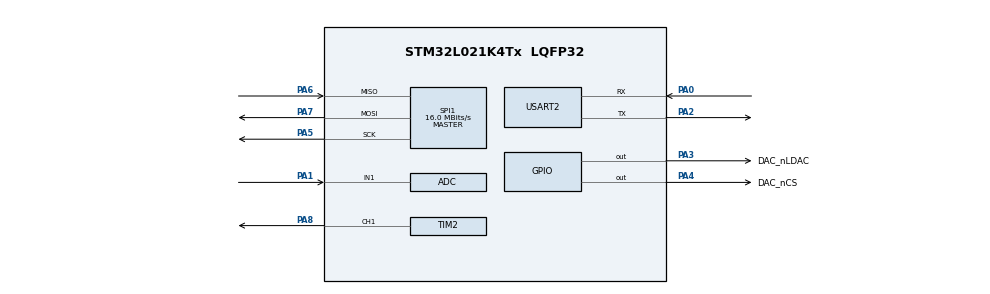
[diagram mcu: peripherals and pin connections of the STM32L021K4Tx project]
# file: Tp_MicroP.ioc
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Mcu.Family=STM32L0
Mcu.Name=STM32L021K4Tx
Mcu.Package=LQFP32
NVIC.TIM21_IRQn=true\:0\:0\:false\:false\:true\:true\:true\:true
PA0-CK_IN.Mode=Asynchronous
PA0-CK_IN.Signal=USART2_RX
PA1.Mode=IN1
PA1.Signal=ADC_IN1
PA13.Mode=Serial_Wire
PA13.Signal=SYS_SWDIO
PA14.Mode=Serial_Wire
PA14.Signal=SYS_SWCLK
PA2.Mode=Asynchronous
PA2.Signal=USART2_TX
PA3.GPIO_Label=DAC_nLDAC
PA3.Signal=GPIO_Output
PA4.GPIO_Label=DAC_nCS
PA4.Signal=GPIO_Output
PA5.Mode=Full_Duplex_Master
PA5.Signal=SPI1_SCK
PA6.Mode=Full_Duplex_Master
PA6.Signal=SPI1_MISO
PA7.Mode=Full_Duplex_Master
PA7.Signal=SPI1_MOSI
PA8.Signal=S_TIM2_CH1
ProjectManager.HeapSize=0x200
ProjectManager.StackSize=0x400
ProjectManager.TargetToolchain=STM32CubeIDE
RCC.AHBFreq_Value=32000000
RCC.APB1Freq_Value=32000000
RCC.APB1TimFreq_Value=32000000
RCC.APB2Freq_Value=32000000
RCC.APB2TimFreq_Value=32000000
RCC.HCLKFreq_Value=32000000
RCC.HSE_VALUE=8000000
RCC.HSI16_VALUE=16000000
RCC.HSI_VALUE=16000000
RCC.LSE_VALUE=32768
RCC.MSIClockRange=RCC_MSIRANGE_6
RCC.MSI_VALUE=4194000
RCC.PLLMUL=RCC_PLLMUL_4
RCC.SYSCLKFreq_VALUE=32000000
RCC.SYSCLKSource=RCC_SYSCLKSOURCE_PLLCLK
RCC.VCOOutputFreq_Value=64000000
SH.S_TIM2_CH1.0=TIM2_CH1,PWM Generation1 CH1
SPI1.CalculateBaudRate=16.0 MBits/s
SPI1.Direction=SPI_DIRECTION_2LINES
SPI1.Mode=SPI_MODE_MASTER
SPI1.VirtualType=VM_MASTER
TIM2.Channel-PWM\ Generation1\ CH1=TIM_CHANNEL_1
TIM2.Period=255
TIM2.Prescaler=125
TIM21.Period=255
TIM21.Prescaler=125
USART2.VirtualMode-Asynchronous=VM_ASYNC
VP_TIM21_VS_ClockSourceINT.Mode=Internal
VP_TIM2_VS_ClockSourceINT.Mode=Internal
board=custom

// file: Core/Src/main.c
/* USER CODE BEGIN Header */
/**
 ******************************************************************************
 * @file           : main.c
 * @brief          : Main program body
 ******************************************************************************
 * @attention
 *
 * <h2><center>&copy; Copyright (c) 2023 STMicroelectronics.
 * All rights reserved.</center></h2>
 *
 * This software component is licensed by ST under BSD 3-Clause license,
 * the "License"; You may not use this file except in compliance with the
 * License. You may obtain a copy of the License at:
 *                        opensource.org/licenses/BSD-3-Clause
 *
 ******************************************************************************
 */
/* USER CODE END Header */
#include "main.h"
#include "adc.h"
#include "spi.h"
#include "tim.h"
#include "usart.h"
#include "gpio.h"

/* USER CODE BEGIN Includes */
#include "Led.h"
/* USER CODE END Includes */

void SystemClock_Config(void);

/* USER CODE BEGIN 0 */
led_t MyLed = {
	.value = 0,
	.sens = LED_UP,
	.timer = TIM2
};

//Fonction appelé lors d'une interruption
/*void HAL_TIM_PeriodElapsedCallback(TIM_HandleTypeDef *htim){
  	if (htim==&htim21)

	}*/
/* USER CODE END 0 */

int main(void)
{

  /* MCU Configuration--------------------------------------------------------*/

  /* Reset of all peripherals, Initializes the Flash interface and the Systick. */
  HAL_Init();

  /* Configure the system clock */
  SystemClock_Config();

  /* Initialize all configured peripherals */
  MX_GPIO_Init();
  MX_USART2_UART_Init();
  MX_ADC_Init();
  MX_TIM2_Init();
  MX_SPI1_Init();
  MX_TIM21_Init();
  /* USER CODE BEGIN 2 */
  //démarrage de l'interruption sur TIM21
  HAL_TIM_Base_Start_IT(&htim21);
  LedStart(&MyLed);
  /* USER CODE END 2 */

  /* Infinite loop */
  /* USER CODE BEGIN WHILE */
	while (1)
	{
		LedPulse(&MyLed);
		LL_mDelay(1);
    /* USER CODE END WHILE */

	}
}

void SystemClock_Config(void)
{
  LL_FLASH_SetLatency(LL_FLASH_LATENCY_1);
  while(LL_FLASH_GetLatency()!= LL_FLASH_LATENCY_1)
  {
  }
  LL_PWR_SetRegulVoltageScaling(LL_PWR_REGU_VOLTAGE_SCALE1);
  LL_RCC_HSI_Enable();

   /* Wait till HSI is ready */
  while(LL_RCC_HSI_IsReady() != 1)
  {

  }
  LL_RCC_HSI_SetCalibTrimming(16);
  LL_RCC_PLL_ConfigDomain_SYS(LL_RCC_PLLSOURCE_HSI, LL_RCC_PLL_MUL_4, LL_RCC_PLL_DIV_2);
  LL_RCC_PLL_Enable();

   /* Wait till PLL is ready */
  while(LL_RCC_PLL_IsReady() != 1)
  {

  }
  LL_RCC_SetAHBPrescaler(LL_RCC_SYSCLK_DIV_1);
  LL_RCC_SetAPB1Prescaler(LL_RCC_APB1_DIV_1);
  LL_RCC_SetAPB2Prescaler(LL_RCC_APB2_DIV_1);
  LL_RCC_SetSysClkSource(LL_RCC_SYS_CLKSOURCE_PLL);

   /* Wait till System clock is ready */
  while(LL_RCC_GetSysClkSource() != LL_RCC_SYS_CLKSOURCE_STATUS_PLL)
  {

  }
  LL_SetSystemCoreClock(32000000);

   /* Update the time base */
  if (HAL_InitTick (TICK_INT_PRIORITY) != HAL_OK)
  {
    Error_Handler();
  }
  LL_RCC_SetUSARTClockSource(LL_RCC_USART2_CLKSOURCE_PCLK1);
}

void Error_Handler(void)
{
	__disable_irq();
	while (1)
	{
	}
}

/************************ (C) COPYRIGHT STMicroelectronics *****END OF FILE****/
